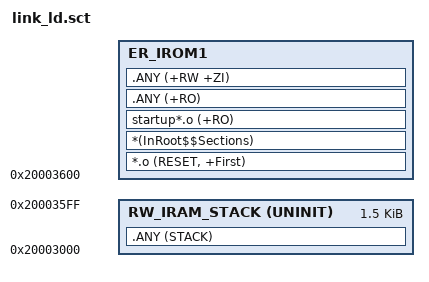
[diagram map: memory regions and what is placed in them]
; *************************************************************
; *** Scatter-Loading Description File generated by uVision ***
; *************************************************************

LR_IROM1 0x20003600 0x4A00  
{
    ER_IROM1 +0
    {
        *.o (RESET, +First)
        *(InRoot$$Sections)
        startup*.o (+RO)
        
        .ANY (+RO)
        .ANY (+RW +ZI)
    }
    
    RW_IRAM_STACK 0x20003600-0x600 UNINIT 0x600
    {
        .ANY (STACK)
    }
}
